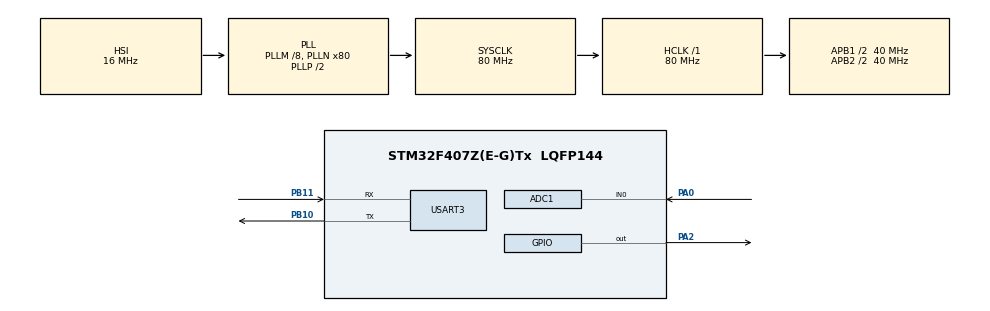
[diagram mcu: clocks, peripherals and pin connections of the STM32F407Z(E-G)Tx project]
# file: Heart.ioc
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ADC1.Channel-3\#ChannelRegularConversion=ADC_CHANNEL_0
ADC1.ContinuousConvMode=ENABLE
ADC1.EOCSelection=ADC_EOC_SEQ_CONV
ADC1.NbrOfConversionFlag=1
ADC1.Rank-3\#ChannelRegularConversion=1
ADC1.SamplingTime-3\#ChannelRegularConversion=ADC_SAMPLETIME_3CYCLES
ADC1.master=1
Mcu.Family=STM32F4
Mcu.Name=STM32F407Z(E-G)Tx
Mcu.Package=LQFP144
NVIC.PriorityGroup=NVIC_PRIORITYGROUP_4
PA0-WKUP.Signal=ADCx_IN0
PA13.Mode=JTAG_5_pins
PA13.Signal=SYS_JTMS-SWDIO
PA14.Mode=JTAG_5_pins
PA14.Signal=SYS_JTCK-SWCLK
PA15.Mode=JTAG_5_pins
PA15.Signal=SYS_JTDI
PA2.Signal=GPIO_Output
PB10.Mode=Asynchronous
PB10.Signal=USART3_TX
PB11.Mode=Asynchronous
PB11.Signal=USART3_RX
PB3.Mode=JTAG_5_pins
PB3.Signal=SYS_JTDO-SWO
PB4.Mode=JTAG_5_pins
PB4.Signal=SYS_JTRST
ProjectManager.HeapSize=0x200
ProjectManager.StackSize=0x400
ProjectManager.TargetToolchain=MDK-ARM V5.27
RCC.48MHZClocksFreq_Value=40000000
RCC.AHBFreq_Value=80000000
RCC.APB1CLKDivider=RCC_HCLK_DIV2
RCC.APB1Freq_Value=40000000
RCC.APB1TimFreq_Value=80000000
RCC.APB2CLKDivider=RCC_HCLK_DIV2
RCC.APB2Freq_Value=40000000
RCC.APB2TimFreq_Value=80000000
RCC.CortexFreq_Value=80000000
RCC.HCLKFreq_Value=80000000
RCC.HSE_VALUE=25000000
RCC.HSI_VALUE=16000000
RCC.LSE_VALUE=32768
RCC.PLLM=8
RCC.PLLN=80
RCC.SYSCLKFreq_VALUE=80000000
RCC.SYSCLKSource=RCC_SYSCLKSOURCE_PLLCLK
RCC.VCOOutputFreq_Value=160000000
SH.ADCx_IN0.0=ADC1_IN0,IN0
USART3.VirtualMode=VM_ASYNC
board=custom

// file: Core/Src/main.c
/* USER CODE BEGIN Header */
/**
  ******************************************************************************
  * @file           : main.c
  * @brief          : Main program body
  ******************************************************************************
  * @attention
  *
  * <h2><center>&copy; Copyright (c) 2021 STMicroelectronics.
  * All rights reserved.</center></h2>
  *
  * This software component is licensed by ST under BSD 3-Clause license,
  * the "License"; You may not use this file except in compliance with the
  * License. You may obtain a copy of the License at:
  *                        opensource.org/licenses/BSD-3-Clause
  *
  ******************************************************************************
  */
/* USER CODE END Header */
#include "main.h"

ADC_HandleTypeDef hadc1;

UART_HandleTypeDef huart3;

void SystemClock_Config(void);
static void MX_GPIO_Init(void);
static void MX_USART3_UART_Init(void);
static void MX_ADC1_Init(void);

int main(void)
{

  /* MCU Configuration--------------------------------------------------------*/

  /* Reset of all peripherals, Initializes the Flash interface and the Systick. */
  HAL_Init();

  /* Configure the system clock */
  SystemClock_Config();

  /* Initialize all configured peripherals */
  MX_GPIO_Init();
  MX_USART3_UART_Init();
  MX_ADC1_Init();
  /* USER CODE BEGIN 2 */
  HAL_ADC_Start(&hadc1);

  /* USER CODE END 2 */

  /* Infinite loop */
  /* USER CODE BEGIN WHILE */
  uint32_t raw;
  char msg[20] ="Hello";

  while (1)
  {
    /* USER CODE END WHILE */

    /* USER CODE BEGIN 3 */
	  HAL_GPIO_TogglePin(GPIOA, GPIO_PIN_2);
	  raw = 0;
	  for (uint16_t i=0;i<1000;i++){
		  HAL_ADC_PollForConversion(&hadc1, HAL_MAX_DELAY);
		  raw +=HAL_ADC_GetValue(&hadc1);
	  }
	  raw *= 0.001;

	  sprintf(msg, "val = %d\n", raw);
	  HAL_UART_Transmit(&huart3, msg, strlen(msg), HAL_MAX_DELAY);

	  HAL_Delay(10);

  }
  /* USER CODE END 3 */
}

void SystemClock_Config(void)
{
  RCC_OscInitTypeDef RCC_OscInitStruct = {0};
  RCC_ClkInitTypeDef RCC_ClkInitStruct = {0};

  /** Configure the main internal regulator output voltage
  */
  __HAL_RCC_PWR_CLK_ENABLE();
  __HAL_PWR_VOLTAGESCALING_CONFIG(PWR_REGULATOR_VOLTAGE_SCALE1);
  /** Initializes the RCC Oscillators according to the specified parameters
  * in the RCC_OscInitTypeDef structure.
  */
  RCC_OscInitStruct.OscillatorType = RCC_OSCILLATORTYPE_HSI;
  RCC_OscInitStruct.HSIState = RCC_HSI_ON;
  RCC_OscInitStruct.HSICalibrationValue = RCC_HSICALIBRATION_DEFAULT;
  RCC_OscInitStruct.PLL.PLLState = RCC_PLL_ON;
  RCC_OscInitStruct.PLL.PLLSource = RCC_PLLSOURCE_HSI;
  RCC_OscInitStruct.PLL.PLLM = 8;
  RCC_OscInitStruct.PLL.PLLN = 80;
  RCC_OscInitStruct.PLL.PLLP = RCC_PLLP_DIV2;
  RCC_OscInitStruct.PLL.PLLQ = 4;
  if (HAL_RCC_OscConfig(&RCC_OscInitStruct) != HAL_OK)
  {
    Error_Handler();
  }
  /** Initializes the CPU, AHB and APB buses clocks
  */
  RCC_ClkInitStruct.ClockType = RCC_CLOCKTYPE_HCLK|RCC_CLOCKTYPE_SYSCLK
                              |RCC_CLOCKTYPE_PCLK1|RCC_CLOCKTYPE_PCLK2;
  RCC_ClkInitStruct.SYSCLKSource = RCC_SYSCLKSOURCE_PLLCLK;
  RCC_ClkInitStruct.AHBCLKDivider = RCC_SYSCLK_DIV1;
  RCC_ClkInitStruct.APB1CLKDivider = RCC_HCLK_DIV2;
  RCC_ClkInitStruct.APB2CLKDivider = RCC_HCLK_DIV2;

  if (HAL_RCC_ClockConfig(&RCC_ClkInitStruct, FLASH_LATENCY_2) != HAL_OK)
  {
    Error_Handler();
  }
}

static void MX_ADC1_Init(void)
{

  ADC_ChannelConfTypeDef sConfig = {0};

  /** Configure the global features of the ADC (Clock, Resolution, Data Alignment and number of conversion)
  */
  hadc1.Instance = ADC1;
  hadc1.Init.ClockPrescaler = ADC_CLOCK_SYNC_PCLK_DIV2;
  hadc1.Init.Resolution = ADC_RESOLUTION_12B;
  hadc1.Init.ScanConvMode = DISABLE;
  hadc1.Init.ContinuousConvMode = ENABLE;
  hadc1.Init.DiscontinuousConvMode = DISABLE;
  hadc1.Init.ExternalTrigConvEdge = ADC_EXTERNALTRIGCONVEDGE_NONE;
  hadc1.Init.ExternalTrigConv = ADC_SOFTWARE_START;
  hadc1.Init.DataAlign = ADC_DATAALIGN_RIGHT;
  hadc1.Init.NbrOfConversion = 1;
  hadc1.Init.DMAContinuousRequests = DISABLE;
  hadc1.Init.EOCSelection = ADC_EOC_SEQ_CONV;
  if (HAL_ADC_Init(&hadc1) != HAL_OK)
  {
    Error_Handler();
  }
  /** Configure for the selected ADC regular channel its corresponding rank in the sequencer and its sample time.
  */
  sConfig.Channel = ADC_CHANNEL_0;
  sConfig.Rank = 1;
  sConfig.SamplingTime = ADC_SAMPLETIME_3CYCLES;
  if (HAL_ADC_ConfigChannel(&hadc1, &sConfig) != HAL_OK)
  {
    Error_Handler();
  }

}

static void MX_USART3_UART_Init(void)
{

  huart3.Instance = USART3;
  huart3.Init.BaudRate = 115200;
  huart3.Init.WordLength = UART_WORDLENGTH_8B;
  huart3.Init.StopBits = UART_STOPBITS_1;
  huart3.Init.Parity = UART_PARITY_NONE;
  huart3.Init.Mode = UART_MODE_TX_RX;
  huart3.Init.HwFlowCtl = UART_HWCONTROL_NONE;
  huart3.Init.OverSampling = UART_OVERSAMPLING_16;
  if (HAL_UART_Init(&huart3) != HAL_OK)
  {
    Error_Handler();
  }

}

static void MX_GPIO_Init(void)
{
  GPIO_InitTypeDef GPIO_InitStruct = {0};

  /* GPIO Ports Clock Enable */
  __HAL_RCC_GPIOA_CLK_ENABLE();
  __HAL_RCC_GPIOB_CLK_ENABLE();

  /*Configure GPIO pin Output Level */
  HAL_GPIO_WritePin(GPIOA, GPIO_PIN_2, GPIO_PIN_RESET);

  /*Configure GPIO pin : PA2 */
  GPIO_InitStruct.Pin = GPIO_PIN_2;
  GPIO_InitStruct.Mode = GPIO_MODE_OUTPUT_PP;
  GPIO_InitStruct.Pull = GPIO_NOPULL;
  GPIO_InitStruct.Speed = GPIO_SPEED_FREQ_LOW;
  HAL_GPIO_Init(GPIOA, &GPIO_InitStruct);

}

void Error_Handler(void)
{
}

/************************ (C) COPYRIGHT STMicroelectronics *****END OF FILE****/
